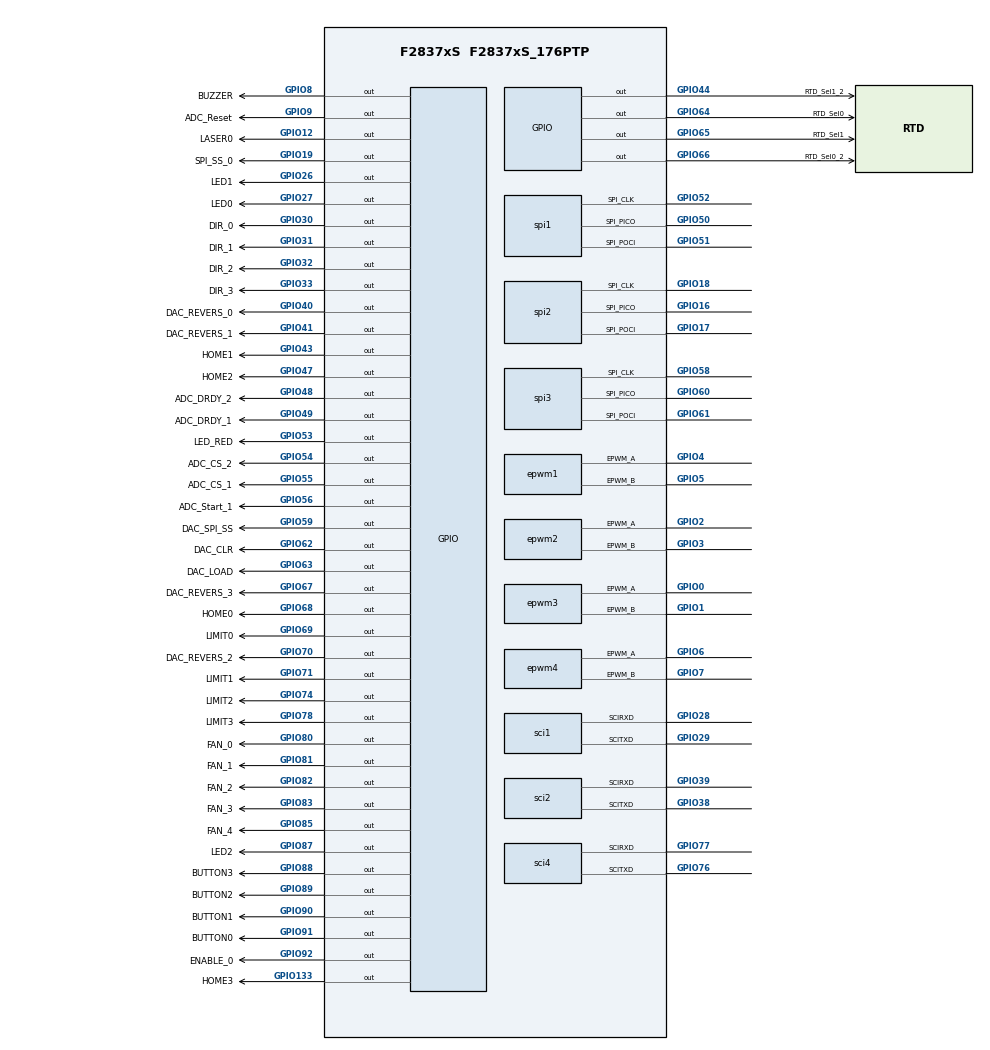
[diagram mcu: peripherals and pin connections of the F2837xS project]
/**
 * @cliArgs --device "F2837xS" --part "F2837xS_176PTP" --package "F2837xS_176PTP" --context "system" --product "C2000WARE@5.04.00.00"
 * @versions {"tool":"1.22.0+3893"}
 */

/**
 * Import the modules used in this configuration.
 */
const epwm   = scripting.addModule("/driverlib/epwm.js", {}, false);
const epwm1  = epwm.addInstance();
const epwm2  = epwm.addInstance();
const epwm3  = epwm.addInstance();
const epwm4  = epwm.addInstance();
const gpio   = scripting.addModule("/driverlib/gpio.js", {}, false);
const gpio1  = gpio.addInstance();
const gpio2  = gpio.addInstance();
const gpio3  = gpio.addInstance();
const gpio4  = gpio.addInstance();
const gpio5  = gpio.addInstance();
const gpio6  = gpio.addInstance();
const gpio7  = gpio.addInstance();
const gpio8  = gpio.addInstance();
const gpio9  = gpio.addInstance();
const gpio10 = gpio.addInstance();
const gpio11 = gpio.addInstance();
const gpio12 = gpio.addInstance();
const gpio13 = gpio.addInstance();
const gpio14 = gpio.addInstance();
const gpio15 = gpio.addInstance();
const gpio16 = gpio.addInstance();
const gpio17 = gpio.addInstance();
const gpio18 = gpio.addInstance();
const gpio19 = gpio.addInstance();
const gpio20 = gpio.addInstance();
const gpio21 = gpio.addInstance();
const gpio22 = gpio.addInstance();
const gpio23 = gpio.addInstance();
const gpio24 = gpio.addInstance();
const gpio25 = gpio.addInstance();
const gpio26 = gpio.addInstance();
const gpio27 = gpio.addInstance();
const gpio28 = gpio.addInstance();
const gpio29 = gpio.addInstance();
const gpio30 = gpio.addInstance();
const gpio31 = gpio.addInstance();
const gpio32 = gpio.addInstance();
const gpio33 = gpio.addInstance();
const gpio34 = gpio.addInstance();
const gpio35 = gpio.addInstance();
const gpio36 = gpio.addInstance();
const gpio37 = gpio.addInstance();
const gpio38 = gpio.addInstance();
const gpio39 = gpio.addInstance();
const gpio40 = gpio.addInstance();
const gpio41 = gpio.addInstance();
const gpio42 = gpio.addInstance();
const gpio43 = gpio.addInstance();
const gpio44 = gpio.addInstance();
const gpio45 = gpio.addInstance();
const gpio46 = gpio.addInstance();
const gpio47 = gpio.addInstance();
const gpio48 = gpio.addInstance();
const gpio49 = gpio.addInstance();
const gpio50 = gpio.addInstance();
const gpio51 = gpio.addInstance();
const gpio52 = gpio.addInstance();
const sci    = scripting.addModule("/driverlib/sci.js", {}, false);
const sci1   = sci.addInstance();
const sci2   = sci.addInstance();
const sci3   = sci.addInstance();
const sci4   = sci.addInstance();
const spi    = scripting.addModule("/driverlib/spi.js", {}, false);
const spi1   = spi.addInstance();
const spi2   = spi.addInstance();
const spi3   = spi.addInstance();

/**
 * Write custom configuration values to the imported modules.
 */
epwm1.$name                  = "myStepMotorEPWM3";
epwm1.epwm.$assign           = "EPWM3";
epwm1.epwm.epwm_aPin.$assign = "GPIO4";
epwm1.epwm.epwm_bPin.$assign = "GPIO5";

epwm2.$name                  = "myStepMotorEPWM2";
epwm2.epwm.$assign           = "EPWM2";
epwm2.epwm.epwm_aPin.$assign = "GPIO2";
epwm2.epwm.epwm_bPin.$assign = "GPIO3";

epwm3.$name                  = "myStepMotorEPWM1";
epwm3.epwm.$assign           = "EPWM1";
epwm3.epwm.epwm_aPin.$assign = "GPIO0";
epwm3.epwm.epwm_bPin.$assign = "GPIO1";

epwm4.$name                  = "myStepMotorEPWM4";
epwm4.epwm.$assign           = "EPWM4";
epwm4.epwm.epwm_aPin.$assign = "GPIO6";
epwm4.epwm.epwm_bPin.$assign = "GPIO7";

gpio1.$name             = "ADC_CS_1";
gpio1.direction         = "GPIO_DIR_MODE_OUT";
gpio1.writeInitialValue = true;
gpio1.initialValue      = 1;
gpio1.gpioPin.$assign   = "GPIO55";

gpio2.$name           = "ADC_Start_1";
gpio2.direction       = "GPIO_DIR_MODE_OUT";
gpio2.gpioPin.$assign = "GPIO56";

gpio3.$name           = "ADC_Reset";
gpio3.gpioPin.$assign = "GPIO9";

gpio4.$name           = "RTD_Sel0";
gpio4.direction       = "GPIO_DIR_MODE_OUT";
gpio4.gpioPin.$assign = "GPIO64";

gpio5.$name           = "RTD_Sel1";
gpio5.direction       = "GPIO_DIR_MODE_OUT";
gpio5.gpioPin.$assign = "GPIO65";

gpio6.$name           = "ADC_DRDY_1";
gpio6.gpioPin.$assign = "GPIO49";

gpio7.$name           = "LED_RED";
gpio7.direction       = "GPIO_DIR_MODE_OUT";
gpio7.gpioPin.$assign = "GPIO53";

gpio8.$name           = "DIR_0";
gpio8.direction       = "GPIO_DIR_MODE_OUT";
gpio8.gpioPin.$assign = "GPIO30";

gpio9.$name             = "ENABLE_0";
gpio9.direction         = "GPIO_DIR_MODE_OUT";
gpio9.writeInitialValue = true;
gpio9.gpioPin.$assign   = "GPIO92";

gpio10.$name             = "SPI_SS_0";
gpio10.direction         = "GPIO_DIR_MODE_OUT";
gpio10.writeInitialValue = true;
gpio10.initialValue      = 1;
gpio10.gpioPin.$assign   = "GPIO19";

gpio11.$name           = "DAC_CLR";
gpio11.direction       = "GPIO_DIR_MODE_OUT";
gpio11.gpioPin.$assign = "GPIO62";

gpio12.$name           = "DAC_LOAD";
gpio12.direction       = "GPIO_DIR_MODE_OUT";
gpio12.gpioPin.$assign = "GPIO63";

gpio13.$name             = "DAC_SPI_SS";
gpio13.direction         = "GPIO_DIR_MODE_OUT";
gpio13.writeInitialValue = true;
gpio13.initialValue      = 1;
gpio13.gpioPin.$assign   = "GPIO59";

gpio14.direction         = "GPIO_DIR_MODE_OUT";
gpio14.$name             = "FAN_0";
gpio14.writeInitialValue = true;
gpio14.gpioPin.$assign   = "GPIO80";

gpio15.$name             = "FAN_1";
gpio15.direction         = "GPIO_DIR_MODE_OUT";
gpio15.writeInitialValue = true;
gpio15.gpioPin.$assign   = "GPIO81";

gpio16.$name             = "FAN_2";
gpio16.direction         = "GPIO_DIR_MODE_OUT";
gpio16.writeInitialValue = true;
gpio16.gpioPin.$assign   = "GPIO82";

gpio17.$name             = "FAN_3";
gpio17.direction         = "GPIO_DIR_MODE_OUT";
gpio17.writeInitialValue = true;
gpio17.gpioPin.$assign   = "GPIO83";

gpio18.$name             = "FAN_4";
gpio18.direction         = "GPIO_DIR_MODE_OUT";
gpio18.writeInitialValue = true;
gpio18.gpioPin.$assign   = "GPIO85";

gpio19.$name             = "LASER0";
gpio19.direction         = "GPIO_DIR_MODE_OUT";
gpio19.writeInitialValue = true;
gpio19.gpioPin.$assign   = "GPIO12";

gpio20.$name             = "LASER1";
gpio20.direction         = "GPIO_DIR_MODE_OUT";
gpio20.writeInitialValue = true;

gpio21.$name             = "LASER2";
gpio21.direction         = "GPIO_DIR_MODE_OUT";
gpio21.writeInitialValue = true;

gpio22.$name             = "LASER3";
gpio22.direction         = "GPIO_DIR_MODE_OUT";
gpio22.writeInitialValue = true;

gpio23.$name             = "LED0";
gpio23.direction         = "GPIO_DIR_MODE_OUT";
gpio23.writeInitialValue = true;
gpio23.gpioPin.$assign   = "GPIO27";

gpio24.$name             = "LED1";
gpio24.direction         = "GPIO_DIR_MODE_OUT";
gpio24.writeInitialValue = true;
gpio24.gpioPin.$assign   = "GPIO26";

gpio25.$name             = "LED2";
gpio25.direction         = "GPIO_DIR_MODE_OUT";
gpio25.writeInitialValue = true;
gpio25.gpioPin.$assign   = "GPIO87";

gpio26.$name           = "LIMIT0";
gpio26.gpioPin.$assign = "GPIO69";

gpio27.$name           = "HOME0";
gpio27.gpioPin.$assign = "GPIO68";

gpio28.$name           = "LIMIT1";
gpio28.gpioPin.$assign = "GPIO71";

gpio29.$name           = "HOME1";
gpio29.gpioPin.$assign = "GPIO43";

gpio30.$name           = "LIMIT2";
gpio30.gpioPin.$assign = "GPIO74";

gpio31.$name           = "HOME2";
gpio31.gpioPin.$assign = "GPIO47";

gpio32.$name           = "LIMIT3";
gpio32.gpioPin.$assign = "GPIO78";

gpio33.$name           = "HOME3";
gpio33.gpioPin.$assign = "GPIO133";

gpio34.$name           = "BUTTON0";
gpio34.gpioPin.$assign = "GPIO91";

gpio35.$name           = "BUTTON1";
gpio35.gpioPin.$assign = "GPIO90";

gpio36.$name           = "BUTTON2";
gpio36.gpioPin.$assign = "GPIO89";

gpio37.$name           = "BUTTON3";
gpio37.gpioPin.$assign = "GPIO88";

gpio38.$name           = "BUZZER";
gpio38.gpioPin.$assign = "GPIO8";

gpio39.$name             = "SPI_SS_1";
gpio39.direction         = "GPIO_DIR_MODE_OUT";
gpio39.writeInitialValue = true;
gpio39.initialValue      = 1;

gpio40.$name             = "SPI_SS_2";
gpio40.direction         = "GPIO_DIR_MODE_OUT";
gpio40.writeInitialValue = true;
gpio40.initialValue      = 1;

gpio41.$name             = "SPI_SS_3";
gpio41.direction         = "GPIO_DIR_MODE_OUT";
gpio41.writeInitialValue = true;
gpio41.initialValue      = 1;

gpio42.$name           = "DIR_1";
gpio42.direction       = "GPIO_DIR_MODE_OUT";
gpio42.gpioPin.$assign = "GPIO31";

gpio43.$name           = "DIR_2";
gpio43.direction       = "GPIO_DIR_MODE_OUT";
gpio43.gpioPin.$assign = "GPIO32";

gpio44.$name           = "DIR_3";
gpio44.direction       = "GPIO_DIR_MODE_OUT";
gpio44.gpioPin.$assign = "GPIO33";

gpio45.$name           = "ADC_CS_2";
gpio45.direction       = "GPIO_DIR_MODE_OUT";
gpio45.gpioPin.$assign = "GPIO54";

gpio46.$name           = "ADC_DRDY_2";
gpio46.gpioPin.$assign = "GPIO48";

gpio47.$name           = "RTD_Sel0_2";
gpio47.direction       = "GPIO_DIR_MODE_OUT";
gpio47.gpioPin.$assign = "GPIO66";

gpio48.$name           = "RTD_Sel1_2";
gpio48.direction       = "GPIO_DIR_MODE_OUT";
gpio48.gpioPin.$assign = "GPIO44";

gpio49.$name             = "DAC_REVERS_0";
gpio49.direction         = "GPIO_DIR_MODE_OUT";
gpio49.writeInitialValue = true;
gpio49.gpioPin.$assign   = "GPIO40";

gpio50.$name             = "DAC_REVERS_1";
gpio50.direction         = "GPIO_DIR_MODE_OUT";
gpio50.writeInitialValue = true;
gpio50.gpioPin.$assign   = "GPIO41";

gpio51.$name             = "DAC_REVERS_2";
gpio51.direction         = "GPIO_DIR_MODE_OUT";
gpio51.writeInitialValue = true;
gpio51.gpioPin.$assign   = "GPIO70";

gpio52.$name             = "DAC_REVERS_3";
gpio52.direction         = "GPIO_DIR_MODE_OUT";
gpio52.writeInitialValue = true;
gpio52.gpioPin.$assign   = "GPIO67";

sci1.$name                 = "BOOT_SCI";
sci1.enabledInterrupts     = ["SCI_INT_RXRDY_BRKDT"];
sci1.rxFifo                = "SCI_FIFO_RX1";
sci1.enabledFIFOInterrupts = ["SCI_INT_RXFF"];
sci1.sci.$assign           = "SCIA";
sci1.sci.scirxdPin.$assign = "GPIO28";
sci1.sci.scitxdPin.$assign = "GPIO29";
sci1.rxQual.$name          = "myGPIOQUAL12";
sci1.txQual.$name          = "myGPIOQUAL13";

sci2.$name                 = "BARCODE_SCI";
sci2.baudRates             = 9600;
sci2.sci.$assign           = "SCIC";
sci2.sci.scirxdPin.$assign = "GPIO39";
sci2.sci.scitxdPin.$assign = "GPIO38";
sci2.rxQual.$name          = "myGPIOQUAL14";
sci2.txQual.$name          = "myGPIOQUAL15";

sci3.$name        = "RS485_SCI";
sci3.baudRates    = 9600;
sci3.sci.$assign  = "SCIB";
sci3.rxQual.$name = "myGPIOQUAL16";
sci3.txQual.$name = "myGPIOQUAL17";

sci4.$name                 = "UART_TTL";
sci4.baudRates             = 9600;
sci4.sci.$assign           = "SCID";
sci4.sci.scirxdPin.$assign = "GPIO77";
sci4.sci.scitxdPin.$assign = "GPIO76";
sci4.rxQual.$name          = "myGPIOQUAL18";
sci4.txQual.$name          = "myGPIOQUAL19";

spi1.$name                   = "mySPI0";
spi1.useInterrupts           = false;
spi1.mode                    = "SPI_MODE_CONTROLLER";
spi1.bitRate                 = 2000000;
spi1.emulationMode           = "SPI_EMULATION_FREE_RUN";
spi1.dataWidth               = "8";
spi1.useFifo                 = false;
spi1.spi.$assign             = "SPIC";
spi1.spi.spi_picoPin.$assign = "GPIO50";
spi1.spi.spi_pociPin.$assign = "GPIO51";
spi1.spi.spi_clkPin.$assign  = "GPIO52";
spi1.picoQual.$name          = "myGPIOQUAL0";
spi1.pociQual.$name          = "myGPIOQUAL1";
spi1.clkQual.$name           = "myGPIOQUAL2";
spi1.pteQual.$name           = "myGPIOQUAL3";

spi2.$name                   = "mySPI1";
spi2.useFifo                 = false;
spi2.useInterrupts           = false;
spi2.mode                    = "SPI_MODE_CONTROLLER";
spi2.emulationMode           = "SPI_EMULATION_FREE_RUN";
spi2.dataWidth               = "8";
spi2.spi.$assign             = "SPIA";
spi2.spi.spi_picoPin.$assign = "GPIO16";
spi2.spi.spi_pociPin.$assign = "GPIO17";
spi2.spi.spi_clkPin.$assign  = "GPIO18";
spi2.picoQual.$name          = "myGPIOQUAL4";
spi2.pociQual.$name          = "myGPIOQUAL5";
spi2.clkQual.$name           = "myGPIOQUAL6";
spi2.pteQual.$name           = "myGPIOQUAL7";

spi3.$name                   = "mySPI2";
spi3.useFifo                 = false;
spi3.useInterrupts           = false;
spi3.dataWidth               = "8";
spi3.mode                    = "SPI_MODE_CONTROLLER";
spi3.emulationMode           = "SPI_EMULATION_FREE_RUN";
spi3.spi.$assign             = "SPIB";
spi3.spi.spi_picoPin.$assign = "GPIO60";
spi3.spi.spi_pociPin.$assign = "GPIO61";
spi3.spi.spi_clkPin.$assign  = "GPIO58";
spi3.picoQual.$name          = "myGPIOQUAL8";
spi3.pociQual.$name          = "myGPIOQUAL9";
spi3.clkQual.$name           = "myGPIOQUAL10";
spi3.clkQual.padConfig       = "PULLUP";
spi3.pteQual.$name           = "myGPIOQUAL11";

/**
 * Pinmux solution for unlocked pins/peripherals. This ensures that minor changes to the automatic solver in a future
 * version of the tool will not impact the pinmux you originally saw.  These lines can be completely deleted in order to
 * re-solve from scratch.
 */
gpio20.gpioPin.$suggestSolution      = "GPIO13";
gpio21.gpioPin.$suggestSolution      = "GPIO14";
gpio22.gpioPin.$suggestSolution      = "GPIO15";
gpio39.gpioPin.$suggestSolution      = "GPIO20";
gpio40.gpioPin.$suggestSolution      = "GPIO21";
gpio41.gpioPin.$suggestSolution      = "GPIO99";
sci3.sci.scirxdPin.$suggestSolution  = "GPIO11";
sci3.sci.scitxdPin.$suggestSolution  = "GPIO10";
spi1.spi.spi_ptePin.$suggestSolution = "GPIO72";
spi2.spi.spi_ptePin.$suggestSolution = "GPIO57";
spi3.spi.spi_ptePin.$suggestSolution = "GPIO23";
